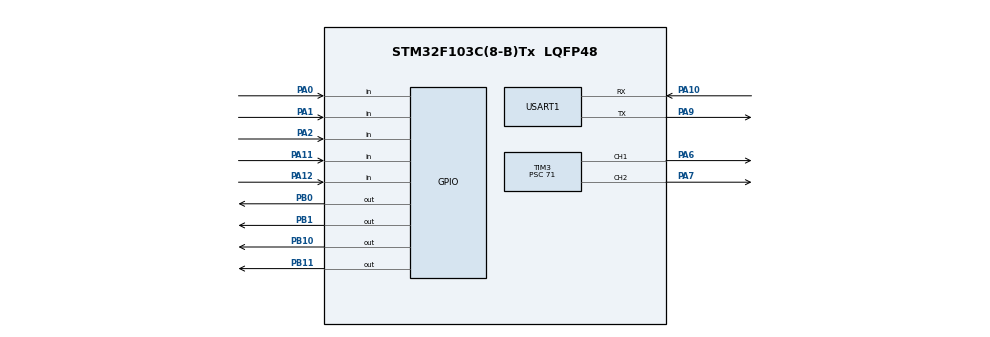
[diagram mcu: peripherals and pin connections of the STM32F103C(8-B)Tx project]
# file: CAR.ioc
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Mcu.Family=STM32F1
Mcu.Name=STM32F103C(8-B)Tx
Mcu.Package=LQFP48
NVIC.PriorityGroup=NVIC_PRIORITYGROUP_4
NVIC.USART1_IRQn=true\:0\:0\:false\:false\:true\:true\:true\:true
PA0-WKUP.GPIO_PuPd=GPIO_PULLUP
PA0-WKUP.Signal=GPIO_Input
PA1.GPIO_PuPd=GPIO_PULLUP
PA1.Signal=GPIO_Input
PA10.Mode=Asynchronous
PA10.Signal=USART1_RX
PA11.GPIO_PuPd=GPIO_PULLUP
PA11.Signal=GPIO_Input
PA12.GPIO_PuPd=GPIO_PULLUP
PA12.Signal=GPIO_Input
PA13.Mode=Serial_Wire
PA13.Signal=SYS_JTMS-SWDIO
PA14.Mode=Serial_Wire
PA14.Signal=SYS_JTCK-SWCLK
PA2.GPIO_PuPd=GPIO_PULLUP
PA2.Signal=GPIO_Input
PA6.Signal=S_TIM3_CH1
PA7.Signal=S_TIM3_CH2
PA9.Mode=Asynchronous
PA9.Signal=USART1_TX
PB0.Signal=GPIO_Output
PB1.Signal=GPIO_Output
PB10.Signal=GPIO_Output
PB11.Signal=GPIO_Output
PD0-OSC_IN.Mode=HSE-External-Oscillator
PD0-OSC_IN.Signal=RCC_OSC_IN
PD1-OSC_OUT.Mode=HSE-External-Oscillator
PD1-OSC_OUT.Signal=RCC_OSC_OUT
ProjectManager.HeapSize=0x200
ProjectManager.StackSize=0x400
ProjectManager.TargetToolchain=MDK-ARM V5.32
RCC.APB1Freq_Value=8000000
RCC.APB2Freq_Value=8000000
SH.S_TIM3_CH1.0=TIM3_CH1,PWM Generation1 CH1
SH.S_TIM3_CH2.0=TIM3_CH2,PWM Generation2 CH2
TIM3.Channel-PWM\ Generation1\ CH1=TIM_CHANNEL_1
TIM3.Channel-PWM\ Generation2\ CH2=TIM_CHANNEL_2
TIM3.Prescaler=71
USART1.VirtualMode=VM_ASYNC
board=custom

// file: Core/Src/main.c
/* USER CODE BEGIN Header */
/**
  ******************************************************************************
  * @file           : main.c
  * @brief          : Main program body
  ******************************************************************************
  * @attention
  *
  * Copyright (c) 2026 STMicroelectronics.
  * All rights reserved.
  *
  * This software is licensed under terms that can be found in the LICENSE file
  * in the root directory of this software component.
  * If no LICENSE file comes with this software, it is provided AS-IS.
  *
  ******************************************************************************
  */
/* USER CODE END Header */
#include "main.h"
/* USER CODE BEGIN Includes */
#include "motor.h"
#include "bluetooth.h"
#include "track.h"
/* USER CODE END Includes */

TIM_HandleTypeDef htim3;

UART_HandleTypeDef huart1;

void SystemClock_Config(void);
static void MX_GPIO_Init(void);
static void MX_TIM3_Init(void);
static void MX_USART1_UART_Init(void);

int main(void)
{

  /* MCU Configuration--------------------------------------------------------*/

  /* Reset of all peripherals, Initializes the Flash interface and the Systick. */
  HAL_Init();

  /* Configure the system clock */
  SystemClock_Config();

  /* Initialize all configured peripherals */
  MX_GPIO_Init();
  MX_TIM3_Init();
  MX_USART1_UART_Init();
  /* USER CODE BEGIN 2 */
HAL_TIM_PWM_Start(&htim3,TIM_CHANNEL_1);
HAL_TIM_PWM_Start(&htim3,TIM_CHANNEL_2);
Bluetooth_Init();
  /* USER CODE END 2 */

  /* Infinite loop */
  /* USER CODE BEGIN WHILE */
  while (1)
  {

		void Blutooth_Process(void);

		if (current_mode == 0)
		{
		   Auto_Track();
		}
		HAL_Delay(10);
    /* USER CODE END WHILE */

  }
}

void SystemClock_Config(void)
{
  RCC_OscInitTypeDef RCC_OscInitStruct = {0};
  RCC_ClkInitTypeDef RCC_ClkInitStruct = {0};

  /** Initializes the RCC Oscillators according to the specified parameters
  * in the RCC_OscInitTypeDef structure.
  */
  RCC_OscInitStruct.OscillatorType = RCC_OSCILLATORTYPE_HSI;
  RCC_OscInitStruct.HSIState = RCC_HSI_ON;
  RCC_OscInitStruct.HSICalibrationValue = RCC_HSICALIBRATION_DEFAULT;
  RCC_OscInitStruct.PLL.PLLState = RCC_PLL_NONE;
  if (HAL_RCC_OscConfig(&RCC_OscInitStruct) != HAL_OK)
  {
    Error_Handler();
  }

  /** Initializes the CPU, AHB and APB buses clocks
  */
  RCC_ClkInitStruct.ClockType = RCC_CLOCKTYPE_HCLK|RCC_CLOCKTYPE_SYSCLK
                              |RCC_CLOCKTYPE_PCLK1|RCC_CLOCKTYPE_PCLK2;
  RCC_ClkInitStruct.SYSCLKSource = RCC_SYSCLKSOURCE_HSI;
  RCC_ClkInitStruct.AHBCLKDivider = RCC_SYSCLK_DIV1;
  RCC_ClkInitStruct.APB1CLKDivider = RCC_HCLK_DIV1;
  RCC_ClkInitStruct.APB2CLKDivider = RCC_HCLK_DIV1;

  if (HAL_RCC_ClockConfig(&RCC_ClkInitStruct, FLASH_LATENCY_0) != HAL_OK)
  {
    Error_Handler();
  }
}

static void MX_TIM3_Init(void)
{

  TIM_MasterConfigTypeDef sMasterConfig = {0};
  TIM_OC_InitTypeDef sConfigOC = {0};

  htim3.Instance = TIM3;
  htim3.Init.Prescaler = 71;
  htim3.Init.CounterMode = TIM_COUNTERMODE_UP;
  htim3.Init.Period = 65535;
  htim3.Init.ClockDivision = TIM_CLOCKDIVISION_DIV1;
  htim3.Init.AutoReloadPreload = TIM_AUTORELOAD_PRELOAD_DISABLE;
  if (HAL_TIM_PWM_Init(&htim3) != HAL_OK)
  {
    Error_Handler();
  }
  sMasterConfig.MasterOutputTrigger = TIM_TRGO_RESET;
  sMasterConfig.MasterSlaveMode = TIM_MASTERSLAVEMODE_DISABLE;
  if (HAL_TIMEx_MasterConfigSynchronization(&htim3, &sMasterConfig) != HAL_OK)
  {
    Error_Handler();
  }
  sConfigOC.OCMode = TIM_OCMODE_PWM1;
  sConfigOC.Pulse = 0;
  sConfigOC.OCPolarity = TIM_OCPOLARITY_HIGH;
  sConfigOC.OCFastMode = TIM_OCFAST_DISABLE;
  if (HAL_TIM_PWM_ConfigChannel(&htim3, &sConfigOC, TIM_CHANNEL_1) != HAL_OK)
  {
    Error_Handler();
  }
  if (HAL_TIM_PWM_ConfigChannel(&htim3, &sConfigOC, TIM_CHANNEL_2) != HAL_OK)
  {
    Error_Handler();
  }
  HAL_TIM_MspPostInit(&htim3);

}

static void MX_USART1_UART_Init(void)
{

  huart1.Instance = USART1;
  huart1.Init.BaudRate = 115200;
  huart1.Init.WordLength = UART_WORDLENGTH_8B;
  huart1.Init.StopBits = UART_STOPBITS_1;
  huart1.Init.Parity = UART_PARITY_NONE;
  huart1.Init.Mode = UART_MODE_TX_RX;
  huart1.Init.HwFlowCtl = UART_HWCONTROL_NONE;
  huart1.Init.OverSampling = UART_OVERSAMPLING_16;
  if (HAL_UART_Init(&huart1) != HAL_OK)
  {
    Error_Handler();
  }

}

static void MX_GPIO_Init(void)
{
  GPIO_InitTypeDef GPIO_InitStruct = {0};

  /* GPIO Ports Clock Enable */
  __HAL_RCC_GPIOD_CLK_ENABLE();
  __HAL_RCC_GPIOA_CLK_ENABLE();
  __HAL_RCC_GPIOB_CLK_ENABLE();

  /*Configure GPIO pin Output Level */
  HAL_GPIO_WritePin(GPIOB, GPIO_PIN_0|GPIO_PIN_1|GPIO_PIN_10|GPIO_PIN_11, GPIO_PIN_RESET);

  /*Configure GPIO pins : PA0 PA1 PA2 PA11
                           PA12 */
  GPIO_InitStruct.Pin = GPIO_PIN_0|GPIO_PIN_1|GPIO_PIN_2|GPIO_PIN_11
                          |GPIO_PIN_12;
  GPIO_InitStruct.Mode = GPIO_MODE_INPUT;
  GPIO_InitStruct.Pull = GPIO_PULLUP;
  HAL_GPIO_Init(GPIOA, &GPIO_InitStruct);

  /*Configure GPIO pins : PB0 PB1 PB10 PB11 */
  GPIO_InitStruct.Pin = GPIO_PIN_0|GPIO_PIN_1|GPIO_PIN_10|GPIO_PIN_11;
  GPIO_InitStruct.Mode = GPIO_MODE_OUTPUT_PP;
  GPIO_InitStruct.Pull = GPIO_NOPULL;
  GPIO_InitStruct.Speed = GPIO_SPEED_FREQ_LOW;
  HAL_GPIO_Init(GPIOB, &GPIO_InitStruct);

}

void Error_Handler(void)
{
  __disable_irq();
  while (1)
  {
  }
}
